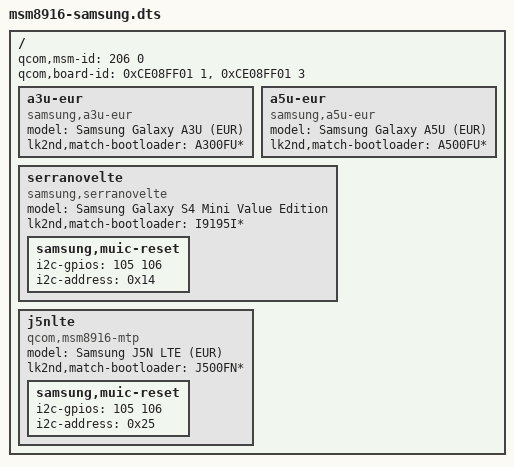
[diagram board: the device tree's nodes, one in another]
// SPDX-License-Identifier: GPL-2.0-only

/dts-v1/;

/include/ "msm8916.dtsi"

/ {
	// This is used by the bootloader to find the correct DTB
	qcom,msm-id = <206 0>;
	qcom,board-id = <0xCE08FF01 1>, <0xCE08FF01 3>;

	// Unfortunately, Samsung uses the same qcom,board-id for all its
	// MSM8916 devices. Therefore, it will always pick this shared device
	// tree and we need to do more manual work to differentiate the devices.
	a3u-eur {
		model = "Samsung Galaxy A3U (EUR)";
		compatible = "samsung,a3u-eur", "qcom,msm8916", "lk2nd,device";
		lk2nd,match-bootloader = "A300FU*";
	};

	a5u-eur {
		model = "Samsung Galaxy A5U (EUR)";
		compatible = "samsung,a5u-eur", "qcom,msm8916", "lk2nd,device";
		lk2nd,match-bootloader = "A500FU*";
	};

	serranovelte {
		model = "Samsung Galaxy S4 Mini Value Edition";
		compatible = "samsung,serranovelte", "qcom,msm8916", "lk2nd,device";
		lk2nd,match-bootloader = "I9195I*";

		samsung,muic-reset {
			i2c-gpios = <105 106>;
			i2c-address = <0x14>;
		};
	};

	j5nlte {
	       model = "Samsung J5N LTE (EUR)";
	       compatible = "qcom,msm8916-mtp", "qcom,msm8916", "qcom,mtp", "qcom,msm8916", "lk2nd,device";
	       lk2nd,match-bootloader = "J500FN*";

	       samsung,muic-reset {
	       			  i2c-gpios = <105 106>;
				  i2c-address = <0x25>;
	       };
	};
};
